# NUC1262AE register map
File version: 1.0
Registers are 32-bit, read-write, reset 0x0 unless marked. A register's access mark holds for its fields unless they carry their own. Offsets are from the block's base; [hi:lo] are bit positions.

## SCS — SYST_SCS Register Map
Base 0xE000E000
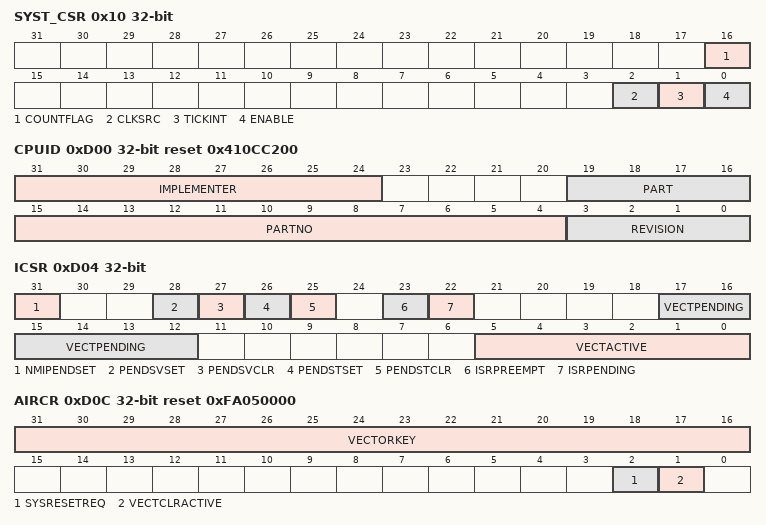
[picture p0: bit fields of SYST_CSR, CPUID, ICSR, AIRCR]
0x10 SYST_CSR — SysTick Control and Status Register
  [16] COUNTFLAG — System Tick Counter Flag. Returns 1 if timer counted to 0 since last time this register is read. COUNTFLAG is set by a count transition from 1 to 0. COUNTFLAG is cleared on read or by a write to the Current Value register.
  [2] CLKSRC — System Tick Clock Source Selection
    0=Clock source is the (optional) external reference clock; 1=Core clock used for SysTick
  [1] TICKINT — System Tick Interrupt Enabled
    0=Counting down to 0 does not cause the SysTick exception to be pended. Software can use COUNTFLAG to determine if a count to zero has occurred; 1=Counting down to 0 will cause the SysTick exception to be pended. Clearing the SysTick current value register by a register write in software will not cause SysTick to be pended
  [0] ENABLE — System Tick Counter Enabled
    0=Counter Disabled; 1=Counter will operate in a multi-shot manner
0x14 SYST_RVR reset not defined — SysTick Reload Value Register
  [23:0] RELOAD — System Tick Reload Value. Value to load into the Current Value register when the counter reaches 0.
0x18 SYST_CVR reset not defined — SysTick Current Value Register
  [23:0] CURRENT — System Tick Current Value. Current counter value. This is the value of the counter at the time it is sampled. The counter does not provide read-modify-write protection. The register is write-clear. A software write of any value will clear the register to 0.
0xD00 CPUID ro reset 0x410CC200
  [31:24] IMPLEMENTER — Implementer Code Assigned by Arm
  [19:16] PART — Architecture of the Processor. Read as 0xC for Armv6-M parts.
  [15:4] PARTNO — Part Number of the Processor. Read as 0xC20.
  [3:0] REVISION — Revision Number. Read as 0x0.
0xD04 ICSR — Interrupt Control and State Register
  [31] NMIPENDSET — NMI Set-pending Bit. Write Operation: Because NMI is the highest-priority exception, normally the processor enters the NMI exception handler as soon as it detects a write of 1 to this bit. Entering the handler then clears this bit to 0. This means a read of this bit by the NMI exception handler returns 1 only if the NMI signal is reasserted while the processor is executing that handler.
    0=No effect. NMI exception not pending; 1=Changes NMI exception state to pending. NMI exception pending
  [28] PENDSVSET — PendSV Set-pending Bit. Write Operation: Note: Writing 1 to this bit is the only way to set the PendSV exception state to pending.
    0=No effect. PendSV exception is not pending; 1=Changes PendSV exception state to pending. PendSV exception is pending
  [27] PENDSVCLR — PendSV Clear-pending Bit. Write Operation: This is a write only bit. When you want to clear PENDSV bit, you must 'write 0 to PENDSVSET and write 1 to PENDSVCLR' at the same time.
    0=No effect; 1=Removes the pending state from the PendSV exception
  [26] PENDSTSET — SysTick Exception Set-pending Bit. Write Operation:
    0=No effect. SysTick exception is not pending; 1=Changes SysTick exception state to pending. SysTick exception is pending
  [25] PENDSTCLR — SysTick Exception Clear-pending Bit. Write Operation: This is a write only bit. When you want to clear PENDST bit, you must 'write 0 to PENDSTSET and write 1 to PENDSTCLR' at the same time.
    0=No effect; 1=Removes the pending state from the SysTick exception
  [23] ISRPREEMPT ro — Interrupt Preempt Bit (Read Only). If Set, a Pending Exception Will Be Serviced on Exit From the Debug Halt State
  [22] ISRPENDING ro — Interrupt Pending Flag, Excluding NMI and Faults (Read Only)
    0=Interrupt not pending; 1=Interrupt pending
  [17:12] VECTPENDING — Number of the Highest Pended Exception
    0=No pending exceptions
  [5:0] VECTACTIVE — Number of the Current Active Exception
    0=Thread mode
0xD0C AIRCR reset 0xFA050000 — Application Interrupt and Reset Control Register
  [31:16] VECTORKEY — Register Access Key. Write Operation: When writing to this register, the VECTORKEY field need to be set to 0x05FA, otherwise the write operation would be ignored. The VECTORKEY filed is used to prevent accidental write to this register from resetting the system or clearing of the exception status. Read Operation: Read as 0xFA05.
  [2] SYSRESETREQ — System Reset Request. Writing this bit 1 will cause a reset signal to be asserted to the chip to indicate a reset is requested. The bit is a write only bit and self-clears as part of the reset sequence.
  [1] VECTCLRACTIVE — Exception Active Status Clear Bit. Reserved for debug use. When writing to the register, user must write 0 to this bit, otherwise behavior is unpredictable.
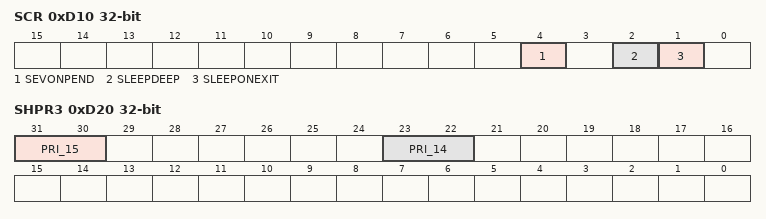
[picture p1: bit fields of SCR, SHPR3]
0xD10 SCR — System Control Register
  [4] SEVONPEND — Send Event on Pending Bit. When an event or interrupt enters pending state, the event signal wakes up the processor from WFE. If the processor is not waiting for an event, the event is registered and affects the next WFE. The processor also wakes up on execution of an SEV instruction or an external event.
    0=Only enabled interrupts or events can wake-up the processor, disabled interrupts are excluded; 1=Enabled events and all interrupts, including disabled interrupts, can wake-up the processor
  [2] SLEEPDEEP — Processor Deep Sleep and Sleep Mode Selection. Controls whether the processor uses sleep or deep sleep as its low power mode:
    0=Sleep mode; 1=Deep Sleep mode
  [1] SLEEPONEXIT — Sleep-on-exit Enable Bit. This bit indicates sleep-on-exit when returning from Handler mode to Thread mode. Setting this bit to 1 enables an interrupt driven application to avoid returning to an empty main application.
    0=Do not sleep when returning to Thread mode; 1=Enter Sleep or Deep Sleep when returning from ISR to Thread mode
0xD1C SHPR2 — System Handler Priority Register 2
  [31:30] PRI_11 — Priority of System Handler 11 - SVCall '0' denotes the highest priority and '3' denotes the lowest priority
0xD20 SHPR3 — System Handler Priority Register 3
  [31:30] PRI_15 — Priority of System Handler 15 - SysTick '0' denotes the highest priority and '3' denotes the lowest priority
  [23:22] PRI_14 — Priority of System Handler 14 - PendSV '0' denotes the highest priority and '3' denotes the lowest priority
